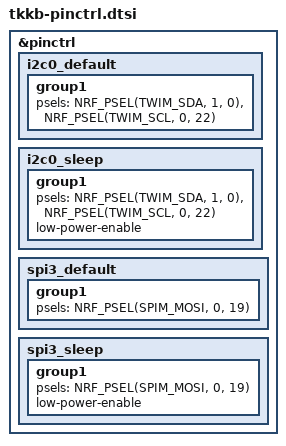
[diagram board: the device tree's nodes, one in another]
/*
 * Copyright (c) 2024 The ZMK Contributors
 * SPDX-License-Identifier: MIT
 */

&pinctrl {
       i2c0_default: i2c0_default {
               group1 {
                       psels = <NRF_PSEL(TWIM_SDA, 1, 0)>,
                               <NRF_PSEL(TWIM_SCL, 0, 22)>;
               };
       };

       i2c0_sleep: i2c0_sleep {
               group1 {
                       psels = <NRF_PSEL(TWIM_SDA, 1, 0)>,
                               <NRF_PSEL(TWIM_SCL, 0, 22)>;
                       low-power-enable;
               };
       };

    spi3_default: spi3_default {
        group1 {
            psels = <NRF_PSEL(SPIM_MOSI, 0, 19)>;
        };
    };

    spi3_sleep: spi3_sleep {
        group1 {
            psels = <NRF_PSEL(SPIM_MOSI, 0, 19)>;
            low-power-enable;
        };
    };
};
